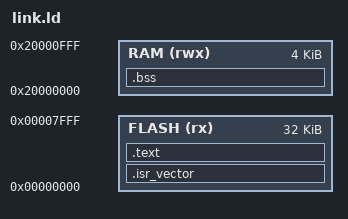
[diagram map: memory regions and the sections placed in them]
MEMORY
{
    FLASH (rx)  : ORIGIN = 0x00000000, LENGTH = 32K
    RAM   (rwx) : ORIGIN = 0x20000000, LENGTH = 4K
}

_estack = ORIGIN(RAM) + LENGTH(RAM);

SECTIONS
{
    .isr_vector :
    {
        KEEP(*(.isr_vector))
    } > FLASH

    .text :
    {
        *(.text*)
    } > FLASH

    .bss :
    {
        *(.bss*)
    } > RAM
}
